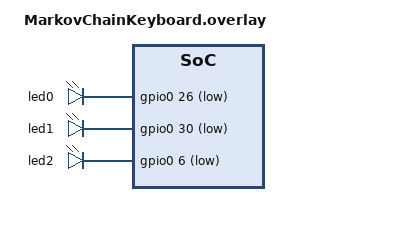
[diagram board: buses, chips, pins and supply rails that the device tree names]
#include <zephyr/dt-bindings/input/input-event-codes.h>
#include <input/processors.dtsi>
#include "MarkovChainKeyboard.dtsi"

&xiao_serial { status = "disabled"; };

&kscan0 {
        col-gpios
            = <&xiao_d 0 GPIO_ACTIVE_HIGH> //Col0
            , <&xiao_d 1 GPIO_ACTIVE_HIGH> //Col1
            , <&xiao_d 2 GPIO_ACTIVE_HIGH> //Col2
            ;
};

/ {
    aliases {
        led-red = &led0;
        led-green = &led1;
        led-blue = &led2;
    };

    leds {
        compatible = "gpio-leds";
        status = "okay";
        led0: led_0 {
            gpios = <&gpio0 26 GPIO_ACTIVE_LOW>;  // red LED, connected to P0.26
        };
        led1: led_1 {
            gpios = <&gpio0 30 GPIO_ACTIVE_LOW>;  // green LED, connected to P0.30
        };
        led2: led_2 {
            gpios = <&gpio0 6 GPIO_ACTIVE_LOW>;  // blue LED, connected to P0.06
        };
    };

};



